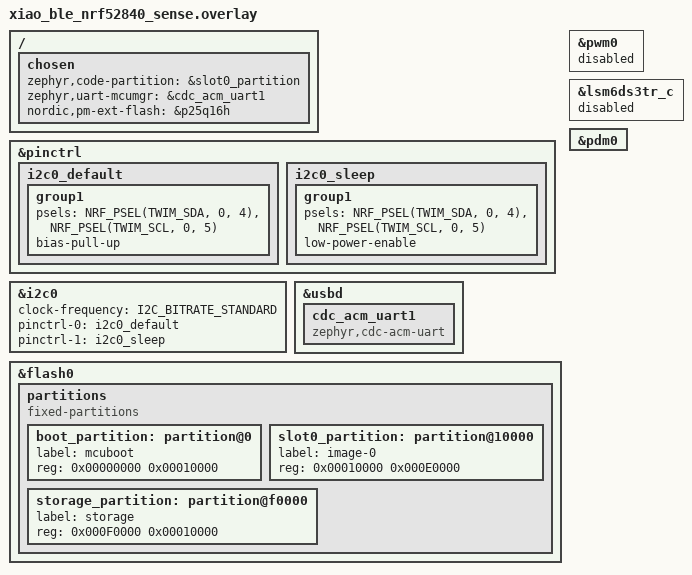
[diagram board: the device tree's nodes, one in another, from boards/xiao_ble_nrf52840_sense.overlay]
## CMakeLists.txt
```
#
# Matter AC Controller for Seeed XIAO BLE (nRF52840)
#

cmake_minimum_required(VERSION 3.20.0)

find_package(Zephyr HINTS $ENV{ZEPHYR_BASE})

project(matter-ac-controller)

# Enable GNU STD support and initialize the Matter Data Model.
include(${ZEPHYR_CONNECTEDHOMEIP_MODULE_DIR}/config/nrfconnect/app/enable-gnu-std.cmake)
include(${ZEPHYR_CONNECTEDHOMEIP_MODULE_DIR}/src/app/chip_data_model.cmake)

# Include paths
set(MATTER_COMMONS_SRC_DIR ${ZEPHYR_NRF_MODULE_DIR}/samples/matter/common/src)
target_include_directories(app PRIVATE
    src
    ${MATTER_COMMONS_SRC_DIR}
)

# Common Matter sources (cherry-picked to avoid DK library dependency)
target_sources(app PRIVATE
    ${MATTER_COMMONS_SRC_DIR}/app/task_executor.cpp
    ${MATTER_COMMONS_SRC_DIR}/app/matter_init.cpp
    ${MATTER_COMMONS_SRC_DIR}/app/matter_event_handler.cpp
)

# Application sources
target_sources(app PRIVATE
    src/main.cpp
    src/app_task.cpp
    src/hw_pairing.cpp
    src/zcl_callbacks.cpp
    src/ir_driver.cpp
    src/ir_protocol.cpp
    src/scd40_manager.cpp
    src/pdm_manager.cpp
    src/shell_commands.cpp
    src/identify_led.cpp
    src/qrcodegen.c
)

set_source_files_properties(
    src/main.cpp
    src/app_task.cpp
    src/hw_pairing.cpp
    src/zcl_callbacks.cpp
    src/ir_driver.cpp
    src/ir_protocol.cpp
    src/scd40_manager.cpp
    src/pdm_manager.cpp
    src/shell_commands.cpp
    src/identify_led.cpp
    PROPERTIES COMPILE_OPTIONS "-Wall;-Wextra;-Werror;-Wno-unused-parameter;-Wno-missing-field-initializers"
)

chip_configure_data_model(app
    INCLUDE_SERVER
    BYPASS_IDL
    GEN_DIR src/zap-generated
    ZAP_FILE ${CMAKE_CURRENT_SOURCE_DIR}/src/ac_controller.zap
)
```

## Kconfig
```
#
# Matter AC Controller
#
mainmenu "Matter AC Controller"

# Sample configuration used for Thread networking
if NET_L2_OPENTHREAD

choice OPENTHREAD_NORDIC_LIBRARY_CONFIGURATION
    default OPENTHREAD_NORDIC_LIBRARY_MTD
endchoice

choice OPENTHREAD_DEVICE_TYPE
    default OPENTHREAD_MTD
endchoice

endif # NET_L2_OPENTHREAD

source "${ZEPHYR_CONNECTEDHOMEIP_MODULE_DIR}/config/nrfconnect/chip-module/Kconfig.features"
source "${ZEPHYR_CONNECTEDHOMEIP_MODULE_DIR}/config/nrfconnect/chip-module/Kconfig.defaults"
source "${ZEPHYR_NRF_MODULE_DIR}/samples/matter/common/src/Kconfig"
source "Kconfig.zephyr"
```

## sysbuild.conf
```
SB_CONFIG_MATTER=y
SB_CONFIG_MATTER_OTA=n

SB_CONFIG_BOOTLOADER_MCUBOOT=y
SB_CONFIG_MCUBOOT_MODE_OVERWRITE_ONLY=y
SB_CONFIG_BOOT_SIGNATURE_TYPE_NONE=y
```

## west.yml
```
manifest:
  version: "0.13"

  remotes:
    - name: nrfconnect
      url-base: https://github.com/nrfconnect

  projects:
    - name: nrf
      remote: nrfconnect
      repo-path: sdk-nrf
      revision: v3.3.0
      import: true

  self:
    path: matter-ac-ncs
```

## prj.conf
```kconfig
#
# Matter AC Controller — prj.conf
#

# --- Matter core ---
CONFIG_CHIP=y
CONFIG_PSA_WANT_ALG_PBKDF2_HMAC=y
CONFIG_PSA_WANT_ALG_HMAC=y
CONFIG_OPENTHREAD_MTD=y
CONFIG_CHIP_ENABLE_PAIRING_AUTOSTART=y
CONFIG_CHIP_PROJECT_CONFIG="src/chip_project_config.h"
CONFIG_STD_CPP17=y

# Extended BLE advertising (improves commissioning reliability)
CONFIG_CHIP_BLE_EXT_ADVERTISING=y
CONFIG_CHIP_BLE_ADVERTISING_DURATION=60

# Device identity
# Vendor/Product IDs are Kconfig int → decimal
CONFIG_CHIP_DEVICE_VENDOR_ID=65521
CONFIG_CHIP_DEVICE_PRODUCT_ID=32769
CONFIG_CHIP_DEVICE_VENDOR_NAME="BRAZENRAKE"
CONFIG_CHIP_DEVICE_PRODUCT_NAME="IR AC Controller"
CONFIG_CHIP_DEVICE_SERIAL_NUMBER="MATTER-AC-001"
CONFIG_CHIP_DEVICE_SOFTWARE_VERSION=1
CONFIG_CHIP_DEVICE_SOFTWARE_VERSION_STRING="1.0.0"
# Discriminator and passcode are derived at runtime from the FICR hardware ID
# by HwPairing::Init() — these Kconfig values are fallback placeholders only.
CONFIG_CHIP_DEVICE_DISCRIMINATOR=0xF00
CONFIG_CHIP_DEVICE_SPAKE2_PASSCODE=20202021

# --- OpenThread features required for Matter commissioning ---
# SLAAC: auto-configure OMR address from the HomePod's on-mesh prefix so SRP
# registers the OMR address (not just ML-EID). Without this the iPhone (Wi-Fi)
# cannot reach the device via the HomePod's backbone router and CASE never starts.
CONFIG_OPENTHREAD_SLAAC=y

# --- Features we do NOT need ---
CONFIG_CHIP_OTA_REQUESTOR=n
CONFIG_CHIP_NFC_ONBOARDING_PAYLOAD=n
CONFIG_CHIP_FACTORY_DATA_NONE=y
CONFIG_BOOTLOADER_MCUBOOT=y
CONFIG_DK_LIBRARY=n

# --- Bluetooth ---
CONFIG_BT_DEVICE_NAME="MatterAC"

# --- Logging via USB-CDC ---
CONFIG_CBPRINTF_FP_SUPPORT=y
CONFIG_LOG=y
CONFIG_LOG_MODE_DEFERRED=y
CONFIG_LOG_RUNTIME_FILTERING=y

# --- USB-CDC shell (uses board's USB_DEVICE_STACK_NEXT default in NCS v3.3.0) ---
CONFIG_UART_LINE_CTRL=y
CONFIG_SHELL=y
CONFIG_SHELL_BACKEND_SERIAL=y
CONFIG_MATTER_LOG_LEVEL_ERR=y
CONFIG_SHELL_MINIMAL=n
CONFIG_LOG_CMDS=y
CONFIG_KERNEL_SHELL=y
CONFIG_SHELL_BACKEND_SERIAL_CHECK_DTR=y
# Second CDC ACM instance for MCUmgr DFU on ACM1 (zephyr,uart-mcumgr in overlay)
CONFIG_CDC_ACM_SERIAL_MULTIPLE_INSTANCES=y

# --- I2C for SCD40 sensor ---
CONFIG_I2C=y

# --- PDM microphone + FFT-based CFAR ACK detector ---
CONFIG_NRFX_PDM=y
CONFIG_GPIO=y
CONFIG_CMSIS_DSP=y
CONFIG_CMSIS_DSP_TRANSFORM=y

# --- Commissioning debug logging ---
# When debugging: uncomment all and set LOG_DEFAULT_LEVEL=3.
# Gives OpenThread join state machine + Matter CommissioningComplete /
# FailSafe / CASE session events. Raise LOG_BUFFER_SIZE for the verbosity.
CONFIG_LOG_DEFAULT_LEVEL=1
# CONFIG_LOG_DEFAULT_LEVEL=3
# CONFIG_OPENTHREAD_DEBUG=y
# CONFIG_OPENTHREAD_LOG_LEVEL_INFO=y
# CONFIG_LOG_BUFFER_SIZE=16384
# CONFIG_MATTER_LOG_LEVEL_INF=y

# --- Stack / safety ---
CONFIG_THREAD_NAME=y
CONFIG_MPU_STACK_GUARD=y
CONFIG_RESET_ON_FATAL_ERROR=n

# --- SMP/MCUmgr for DFU over USB-CDC ACM1 ---
CONFIG_MCUMGR=y
CONFIG_MCUMGR_GRP_IMG=y
CONFIG_MCUMGR_GRP_OS=y
CONFIG_IMG_MANAGER=y
CONFIG_NET_BUF=y
CONFIG_ZCBOR=y
CONFIG_CRC=y
CONFIG_FLASH_MAP=y
CONFIG_STREAM_FLASH=y
CONFIG_FLASH=y
CONFIG_SETTINGS=y
CONFIG_BASE64=y
CONFIG_MCUMGR_TRANSPORT_UART=y
CONFIG_MCUMGR_TRANSPORT_UART_MTU=2048
CONFIG_MCUMGR_TRANSPORT_NETBUF_SIZE=2048
CONFIG_UART_MCUMGR_RX_BUF_SIZE=512
CONFIG_UART_MCUMGR_RX_BUF_COUNT=8
```

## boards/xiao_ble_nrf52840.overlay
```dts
/*
 * Devicetree overlay for Seeed XIAO BLE — Matter AC Controller
 *
 * - Disable USB (save RAM, we use J-Link + RTT)
 * - Reclaim flash from SoftDevice + bootloader
 * - Disable Zephyr PWM0 (IR driver uses NRF_PWM0 registers directly)
 * - I2C0 (TWIM0) for SCD40 sensor (P0.04 SDA / P0.05 SCL)
 */

/* Remap I2C0 pins to P0.04/P0.05 (board default is P0.07/P0.27 for
 * the Sense variant's IMU) and enable internal pull-ups. */
&pinctrl {
    i2c0_default: i2c0_default {
        group1 {
            psels = <NRF_PSEL(TWIM_SDA, 0, 4)>,
                    <NRF_PSEL(TWIM_SCL, 0, 5)>;
            bias-pull-up;
        };
    };
    i2c0_sleep: i2c0_sleep {
        group1 {
            psels = <NRF_PSEL(TWIM_SDA, 0, 4)>,
                    <NRF_PSEL(TWIM_SCL, 0, 5)>;
            low-power-enable;
        };
    };
};

&i2c0 {
    status = "okay";
    clock-frequency = <I2C_BITRATE_STANDARD>;
    pinctrl-0 = <&i2c0_default>;
    pinctrl-1 = <&i2c0_sleep>;
    pinctrl-names = "default", "sleep";
};

/* USB-CDC: shell on ACM0 (usb_cdc_acm_uart, via board DTS), SMP/DFU on ACM1 */
&usbd {
    status = "okay";
    cdc_acm_uart1: cdc_acm_uart1 {
        compatible = "zephyr,cdc-acm-uart";
    };
};

/* Replace Adafruit-layout partitions with MCUboot-compatible labels.
 * Addresses must match pm_static_xiao_ble_nrf52840_sense.yml.
 * image_signing.cmake needs slot0_partition to determine the slot size. */
&flash0 {
    /delete-node/ partitions;

    partitions {
        compatible = "fixed-partitions";
        #address-cells = <1>;
        #size-cells = <1>;

        boot_partition: partition@0 {
            label = "mcuboot";
            reg = <0x00000000 0x00010000>;
        };

        slot0_partition: partition@10000 {
            label = "image-0";
            reg = <0x00010000 0x000E0000>;
        };

        storage_partition: partition@f0000 {
            label = "storage";
            reg = <0x000F0000 0x00010000>;
        };
    };
};

/ {
    chosen {
        zephyr,code-partition = &slot0_partition;
        zephyr,uart-mcumgr = &cdc_acm_uart1;
        nordic,pm-ext-flash = &p25q16h;
    };
};

/* Disable Zephyr PWM0 — the IR driver configures NRF_PWM0 registers
 * directly to work around the polarity trick needed for 0% duty. */
&pwm0 { status = "disabled"; };
```

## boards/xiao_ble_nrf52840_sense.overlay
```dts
/*
 * Devicetree overlay for Seeed XIAO BLE Sense — Matter AC Controller
 *
 * Extends the base XIAO BLE settings with PDM microphone enablement.
 * All other settings (I2C remap, USB-CDC dual-port, PWM0 disable)
 * are identical to xiao_ble_nrf52840.overlay.
 *
 * PDM pinctrl (pdm0_default / pdm0_sleep) is already defined in:
 *   zephyr/boards/seeed/xiao_ble/xiao_ble-pinctrl.dtsi (lines 55–68)
 * We only need to set status = "okay" here.
 */

/* Remap I2C0 pins to P0.04/P0.05 (board default is P0.07/P0.27 for
 * the Sense variant's IMU) and enable internal pull-ups. */
&pinctrl {
    i2c0_default: i2c0_default {
        group1 {
            psels = <NRF_PSEL(TWIM_SDA, 0, 4)>,
                    <NRF_PSEL(TWIM_SCL, 0, 5)>;
            bias-pull-up;
        };
    };
    i2c0_sleep: i2c0_sleep {
        group1 {
            psels = <NRF_PSEL(TWIM_SDA, 0, 4)>,
                    <NRF_PSEL(TWIM_SCL, 0, 5)>;
            low-power-enable;
        };
    };
};

&i2c0 {
    status = "okay";
    clock-frequency = <I2C_BITRATE_STANDARD>;
    pinctrl-0 = <&i2c0_default>;
    pinctrl-1 = <&i2c0_sleep>;
    pinctrl-names = "default", "sleep";

};

/* USB-CDC: shell on ACM0 (usb_cdc_acm_uart, via board DTS), SMP/DFU on ACM1 */
&usbd {
    status = "okay";
    cdc_acm_uart1: cdc_acm_uart1 {
        compatible = "zephyr,cdc-acm-uart";
    };
};

/* Replace Adafruit-layout partitions with MCUboot-compatible labels.
 * Addresses must match pm_static_xiao_ble_nrf52840_sense.yml.
 * image_signing.cmake needs slot0_partition to determine the slot size. */
&flash0 {
    /delete-node/ partitions;

    partitions {
        compatible = "fixed-partitions";
        #address-cells = <1>;
        #size-cells = <1>;

        boot_partition: partition@0 {
            label = "mcuboot";
            reg = <0x00000000 0x00010000>;
        };

        slot0_partition: partition@10000 {
            label = "image-0";
            reg = <0x00010000 0x000E0000>;
        };

        storage_partition: partition@f0000 {
            label = "storage";
            reg = <0x000F0000 0x00010000>;
        };
    };
};

/ {
    chosen {
        zephyr,code-partition = &slot0_partition;
        zephyr,uart-mcumgr = &cdc_acm_uart1;
        nordic,pm-ext-flash = &p25q16h;
    };
};


/* Disable Zephyr PWM0 — the IR driver configures NRF_PWM0 registers
 * directly to work around the polarity trick needed for 0% duty. */
&pwm0 { status = "disabled"; };

/* IMU is on I2C0 which is remapped to SCD40 pins — disable to suppress init error. */
&lsm6ds3tr_c { status = "disabled"; };

/* Enable PDM0 — pinctrl already defined in xiao_ble-pinctrl.dtsi.
 * The Sense board DTS sets clock-source and pinctrl; we only add status. */
&pdm0 {
    status = "okay";
};
```

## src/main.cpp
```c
/*
 * Matter AC Controller — main entry point.
 */

#include "app_task.h"

#include <zephyr/logging/log.h>

LOG_MODULE_REGISTER(app, CONFIG_MATTER_LOG_LEVEL);

int main() {

    CHIP_ERROR err = AppTask::Instance().StartApp();

    LOG_ERR("Exited with code %" CHIP_ERROR_FORMAT, err.Format());
    return err == CHIP_NO_ERROR ? EXIT_SUCCESS : EXIT_FAILURE;
}
```

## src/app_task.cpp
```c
/*
 * Matter AC Controller — application task.
 *
 * Simplified from the Nordic thermostat sample: no DK buttons/LEDs,
 * no temperature sensor manager, no binding handler.  Initializes
 * the Matter stack, IR driver, SCD40 sensor, and runs the task loop.
 */

#include "app_task.h"
#include "hw_pairing.h"
#include "ir_driver.h"
#include "scd40_manager.h"
#include "pdm_manager.h"

#include "app/matter_init.h"
#include "app/task_executor.h"
#include "identify_led.h"

#include <app/DefaultTimerDelegate.h>
#include <app/clusters/identify-server/IdentifyCluster.h>
#include <data-model-providers/codegen/CodegenDataModelProvider.h>
#include <setup_payload/OnboardingCodesUtil.h>

#include <zephyr/logging/log.h>

extern void zcl_callbacks_ready(void);

/* nrf_matter_cluster_init_run_all is called by matter_init.cpp::StartServer() in NCS v3.3.0.
 * We don't register any entries via NRF_MATTER_CLUSTER_INIT so this is a no-op. */
extern "C" bool nrf_matter_cluster_init_run_all(void) { return true; }

LOG_MODULE_DECLARE(app, CONFIG_MATTER_LOG_LEVEL);

using namespace ::chip;
using namespace ::chip::app;
using namespace ::chip::DeviceLayer;

namespace {
constexpr EndpointId kThermostatEndpointId = 1;

/* Identify cluster — new ServerClusterInterface model (NCS v3.3.0 / CHIP SDK 2.9.x).
 * ZAP marks Identify attributes EXTERNAL_STORAGE, so they must be served by a registered
 * ServerClusterInterface; the legacy Identify shim silently swallows Register() errors.
 * Using RegisteredServerCluster directly mirrors the NCS thermostat sample pattern and
 * surfaces any registration failure. Endpoints 1-3 all carry Identify in the ZAP config. */

chip::app::DefaultTimerDelegate gIdTimer1, gIdTimer2, gIdTimer3;
chip::app::RegisteredServerCluster<chip::app::Clusters::IdentifyCluster>
    gIdCluster1(chip::app::Clusters::IdentifyCluster::Config(1, gIdTimer1)
        .WithDelegate(&identify_led_delegate())
        .WithIdentifyType(chip::app::Clusters::Identify::IdentifyTypeEnum::kVisibleIndicator)),
    gIdCluster2(chip::app::Clusters::IdentifyCluster::Config(2, gIdTimer2)
        .WithDelegate(&identify_led_delegate())
        .WithIdentifyType(chip::app::Clusters::Identify::IdentifyTypeEnum::kVisibleIndicator)),
    gIdCluster3(chip::app::Clusters::IdentifyCluster::Config(3, gIdTimer3)
        .WithDelegate(&identify_led_delegate())
        .WithIdentifyType(chip::app::Clusters::Identify::IdentifyTypeEnum::kVisibleIndicator));

} /* namespace */

CHIP_ERROR AppTask::Init() {
    /* Derive discriminator + SPAKE2+ passcode from FICR hardware ID. */
    ReturnErrorOnFailure(HwPairing::Init());

    /* Initialize and start the Matter server. */
    ReturnErrorOnFailure(Nrf::Matter::PrepareServer());
    ReturnErrorOnFailure(Nrf::Matter::StartServer());

    /* Register Identify clusters for all endpoints that declare them in the ZAP config.
     * Must happen after StartServer() so the registry context is set and Startup() fires. */
    {
        auto & reg = CodegenDataModelProvider::Instance().Registry();
        for (auto * entry : { &gIdCluster1.Registration(),
                               &gIdCluster2.Registration(),
                               &gIdCluster3.Registration() }) {
            CHIP_ERROR err = reg.Register(*entry);
            if (err != CHIP_NO_ERROR) {
                LOG_ERR("Identify Register failed: %" CHIP_ERROR_FORMAT, err.Format());
            }
        }
    }

    /* Initialize IR driver (PWM-based 38kHz carrier on P0.02). */
    int ret = ir_driver_init();
    if (ret) {
        LOG_ERR("IR driver init failed: %d", ret);
    }

    /* Initialize SCD40 sensor (I2C0, 30s polling). */
    ret = scd40_manager_init();
    if (ret) {
        LOG_ERR("SCD40 init failed: %d (sensor may not be connected)", ret);
    }

    /* Initialize PDM microphone (2kHz beep detection for IR ACK). */
    pdm_manager_init();

    /* Enable IR transmission now that init is complete.
     * This prevents MatterPostAttributeChangeCallback from firing
     * IR during Matter stack attribute restoration at boot. */
    zcl_callbacks_ready();

    return CHIP_NO_ERROR;
}

CHIP_ERROR AppTask::StartApp() {
    ReturnErrorOnFailure(Init());

    while (true) {
        Nrf::DispatchNextTask();
    }

    return CHIP_NO_ERROR;
}
```

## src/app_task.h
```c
/*
 * Matter AC Controller — application task.
 */

#pragma once

#include <platform/CHIPDeviceLayer.h>

class AppTask {
public:
	static AppTask &Instance()
	{
		static AppTask sAppTask;
		return sAppTask;
	}

	CHIP_ERROR StartApp();

private:
	CHIP_ERROR Init();
};
```

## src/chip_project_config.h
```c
/*
 * CHIP project configuration overrides for Matter AC Controller.
 */

#pragma once

#define CHIP_DEVICE_CONFIG_DYNAMIC_ENDPOINT_COUNT 0

/* MRP intervals for Thread MTD.
 *
 * NCS v3.3.0 Matter SDK (v2.9.2): GetLocalMRPConfig() returns Missing() when
 * the local config matches GetDefaultMRPConfig() (idle=500ms, active=300ms).
 * Missing() causes CopyTxtRecord to skip SII/SAI/SAT from the operational SRP
 * advertisement, and Apple Home will not initiate CASE without those TXT records.
 *
 * Setting idle to 4300ms (typical Thread MTD polling interval recommendation)
 * makes the config differ from default, so GetLocalMRPConfig() returns Value()
 * and the TXT records are included in the SRP advertisement.
 */
#define CHIP_CONFIG_MRP_LOCAL_IDLE_RETRY_INTERVAL   (4300_ms32)
#define CHIP_CONFIG_MRP_LOCAL_ACTIVE_RETRY_INTERVAL (300_ms32)
```

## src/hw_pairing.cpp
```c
/*
 * Derive Matter pairing credentials from the nRF52840 FICR hardware device ID.
 *
 * The FICR DEVICEID registers hold a 64-bit value that is unique per die and
 * programmed at the factory.  We domain-separate FNV-1a hashes of those bytes
 * to produce a 12-bit discriminator, a valid passcode, a 16-byte PBKDF2 salt,
 * and a SPAKE2+ verifier — all without any runtime storage or factory data.
 */

#include "hw_pairing.h"

#include <crypto/CHIPCryptoPAL.h>
#include <lib/core/CHIPError.h>
#include <lib/support/Span.h>
#include <platform/CommissionableDataProvider.h>

#include <nrfx.h>
#include <zephyr/logging/log.h>

#include <string.h>

LOG_MODULE_REGISTER(hw_pairing, CONFIG_LOG_DEFAULT_LEVEL);

using namespace chip;
using namespace chip::Crypto;
using namespace chip::DeviceLayer;

/* ---- FNV-1a 32-bit ---------------------------------------------------- */

static constexpr uint32_t kFnvBasis = 2166136261u;
static constexpr uint32_t kFnvPrime = 16777619u;

static uint32_t fnv1a32(const uint8_t *data, size_t len, uint32_t seed)
{
    uint32_t h = seed;
    for (size_t i = 0; i < len; i++) {
        h ^= data[i];
        h *= kFnvPrime;
    }
    return h;
}

/* ---- Passcode sanitisation -------------------------------------------- */

/* Matter spec Table 39 — forbidden passcodes. */
static constexpr uint32_t kForbidden[] = {
    00000000u, 11111111u, 22222222u, 33333333u, 44444444u,
    55555555u, 66666666u, 77777777u, 88888888u, 99999999u,
    12345678u, 87654321u,
};

static uint32_t make_passcode(uint32_t h)
{
    /* Map to [1, 99999998]. */
    uint32_t code = (h % 99999998u) + 1u;

    for (uint32_t f : kForbidden) {
        if (code == f) {
            /* Bump by one; no two forbidden values are adjacent. */
            code = (code % 99999998u) + 1u;
            break;
        }
    }
    return code;
}

/* ---- CommissionableDataProvider --------------------------------------- */

namespace {

class HwCommissionableDataProvider : public CommissionableDataProvider
{
public:
    CHIP_ERROR Init();

    CHIP_ERROR GetSetupDiscriminator(uint16_t & discriminator) override;
    CHIP_ERROR SetSetupDiscriminator(uint16_t) override { return CHIP_ERROR_NOT_IMPLEMENTED; }
    CHIP_ERROR GetSpake2pIterationCount(uint32_t & iterationCount) override;
    CHIP_ERROR GetSpake2pSalt(MutableByteSpan & saltBuf) override;
    CHIP_ERROR GetSpake2pVerifier(MutableByteSpan & verifierBuf,
                                  size_t & verifierLen) override;
    CHIP_ERROR GetSetupPasscode(uint32_t & passcode) override;
    CHIP_ERROR SetSetupPasscode(uint32_t) override { return CHIP_ERROR_NOT_IMPLEMENTED; }

private:
    static constexpr uint32_t kIterations   = 1000;
    static constexpr size_t   kSaltLen      = 16;
    static constexpr size_t   kVerifierLen  = kSpake2p_VerifierSerialized_Length;

    uint16_t mDiscriminator = 0;
    uint32_t mPasscode      = 0;
    uint8_t  mSalt[kSaltLen];
    uint8_t  mVerifier[kVerifierLen];
    bool     mRawReady     = false;
    bool     mVerifierReady = false;
};

HwCommissionableDataProvider gProvider;

} // namespace

CHIP_ERROR HwCommissionableDataProvider::Init()
{
    /* Read the 64-bit FICR unique device ID. */
    uint32_t id0 = NRF_FICR->DEVICEID[0];
    uint32_t id1 = NRF_FICR->DEVICEID[1];

    uint8_t raw[8];
    memcpy(raw,     &id0, 4);
    memcpy(raw + 4, &id1, 4);

    /* Discriminator — 12 bits. */
    uint32_t hDisc  = fnv1a32(raw, sizeof(raw), 0xD15C0001u);
    mDiscriminator  = static_cast<uint16_t>(hDisc & 0x0FFFu);

    /* Passcode — [1, 99999998] minus forbidden values. */
    uint32_t hPass = fnv1a32(raw, sizeof(raw), 0xD15C0002u);
    mPasscode      = make_passcode(hPass);

    /* Salt — 16 bytes from four domain-separated hashes. */
    for (int i = 0; i < 4; i++) {
        uint32_t hs = fnv1a32(raw, sizeof(raw),
                               static_cast<uint32_t>(0xD15C0003u + i));
        memcpy(mSalt + (i * 4), &hs, 4);
    }

    mRawReady = true;

    LOG_INF("HW pairing: discriminator=%04u  passcode=%08u",
            mDiscriminator, mPasscode);
    return CHIP_NO_ERROR;
}

CHIP_ERROR HwCommissionableDataProvider::GetSetupDiscriminator(uint16_t & discriminator)
{
    VerifyOrReturnError(mRawReady, CHIP_ERROR_INCORRECT_STATE);
    discriminator = mDiscriminator;
    return CHIP_NO_ERROR;
}

CHIP_ERROR HwCommissionableDataProvider::GetSpake2pIterationCount(uint32_t & iterationCount)
{
    iterationCount = kIterations;
    return CHIP_NO_ERROR;
}

CHIP_ERROR HwCommissionableDataProvider::GetSpake2pSalt(MutableByteSpan & saltBuf)
{
    VerifyOrReturnError(mRawReady, CHIP_ERROR_INCORRECT_STATE);
    VerifyOrReturnError(saltBuf.size() >= kSaltLen, CHIP_ERROR_BUFFER_TOO_SMALL);
    memcpy(saltBuf.data(), mSalt, kSaltLen);
    saltBuf.reduce_size(kSaltLen);
    return CHIP_NO_ERROR;
}

CHIP_ERROR HwCommissionableDataProvider::GetSpake2pVerifier(MutableByteSpan & verifierBuf,
                                                             size_t & verifierLen)
{
    VerifyOrReturnError(mRawReady, CHIP_ERROR_INCORRECT_STATE);

    if (!mVerifierReady) {
        /* PSA is now initialized (called after PrepareServer). */
        LOG_INF("HW pairing: computing SPAKE2+ verifier (PBKDF2, %u iterations)...", kIterations);
        Spake2pVerifier verifier;
        CHIP_ERROR err = verifier.Generate(kIterations, ByteSpan(mSalt, kSaltLen), mPasscode);
        if (err != CHIP_NO_ERROR) {
            LOG_ERR("HW pairing: Spake2pVerifier::Generate failed: %" CHIP_ERROR_FORMAT, err.Format());
            return err;
        }
        MutableByteSpan span(mVerifier, kVerifierLen);
        ReturnErrorOnFailure(verifier.Serialize(span));
        mVerifierReady = true;
        LOG_INF("HW pairing: verifier ready");
    }

    VerifyOrReturnError(verifierBuf.size() >= kVerifierLen, CHIP_ERROR_BUFFER_TOO_SMALL);
    memcpy(verifierBuf.data(), mVerifier, kVerifierLen);
    verifierBuf.reduce_size(kVerifierLen);
    verifierLen = kVerifierLen;
    return CHIP_NO_ERROR;
}

CHIP_ERROR HwCommissionableDataProvider::GetSetupPasscode(uint32_t & passcode)
{
    VerifyOrReturnError(mRawReady, CHIP_ERROR_INCORRECT_STATE);
    passcode = mPasscode;
    return CHIP_NO_ERROR;
}

/* ---- Public API ------------------------------------------------------- */

CHIP_ERROR HwPairing::Init()
{
    ReturnErrorOnFailure(gProvider.Init());
    SetCommissionableDataProvider(&gProvider);
    return CHIP_NO_ERROR;
}
```

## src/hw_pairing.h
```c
/*
 * Derive discriminator and SPAKE2+ passcode from the nRF52840 FICR hardware
 * device ID so every unit gets unique pairing credentials without factory data.
 */

#pragma once

#include <lib/core/CHIPError.h>

namespace HwPairing {

/* Compute credentials from FICR, build the SPAKE2+ verifier, and register a
 * CommissionableDataProvider.  Must be called before PrepareServer(). */
CHIP_ERROR Init();

} // namespace HwPairing
```

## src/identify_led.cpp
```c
/*
 * Identify cluster feedback: 2 Hz blue LED blink.
 *
 * Implements IdentifyDelegate for the new ServerClusterInterface model used
 * in NCS v3.3.0 / CHIP SDK 2.9.x.  The LED blinks while the Matter Identify
 * timer counts down (OnIdentifyStart / OnIdentifyStop) and also when triggered
 * directly by the "matter identify" shell command (identify_led_trigger).
 */

#include <zephyr/drivers/gpio.h>
#include <zephyr/kernel.h>

#include <app/clusters/identify-server/IdentifyCluster.h>
#include "identify_led.h"

using namespace chip::app::Clusters;

/* Blue LED: P0.30, active-low (common anode RGB on XIAO nRF52840). */
static const struct gpio_dt_spec led_blue = GPIO_DT_SPEC_GET(DT_ALIAS(led2), gpios);

static struct k_timer blink_timer;
static struct k_timer stop_timer;   /* auto-stop for shell-triggered blink */
static struct k_work  blink_work;
static bool           blink_on;

static void blink_work_fn(struct k_work *)
{
    blink_on = !blink_on;
    gpio_pin_set_dt(&led_blue, (int)blink_on);
}

static void blink_timer_fn(struct k_timer *)
{
    k_work_submit(&blink_work);
}

static void stop_timer_fn(struct k_timer *)
{
    k_timer_stop(&blink_timer);
    gpio_pin_set_dt(&led_blue, 0);
}

static void start_blink()
{
    k_timer_stop(&stop_timer);
    blink_on = false;
    k_timer_start(&blink_timer, K_MSEC(250), K_MSEC(250));
}

static void stop_blink()
{
    k_timer_stop(&stop_timer);
    k_timer_stop(&blink_timer);
    gpio_pin_set_dt(&led_blue, 0);
}

class LedIdentifyDelegate : public IdentifyDelegate
{
public:
    void OnIdentifyStart(IdentifyCluster &) override { start_blink(); }
    void OnIdentifyStop(IdentifyCluster &) override  { stop_blink(); }
    void OnTriggerEffect(IdentifyCluster &) override { start_blink(); }
    bool IsTriggerEffectEnabled() const override     { return true; }
};

static LedIdentifyDelegate gDelegate;

IdentifyDelegate & identify_led_delegate()
{
    return gDelegate;
}

void identify_led_trigger()
{
    start_blink();
    k_timer_start(&stop_timer, K_SECONDS(5), K_NO_WAIT);
}

static int identify_led_init(void)
{
    if (!gpio_is_ready_dt(&led_blue)) {
        return -ENODEV;
    }
    gpio_pin_configure_dt(&led_blue, GPIO_OUTPUT_INACTIVE);
    k_work_init(&blink_work, blink_work_fn);
    k_timer_init(&blink_timer, blink_timer_fn, NULL);
    k_timer_init(&stop_timer, stop_timer_fn, NULL);
    return 0;
}

SYS_INIT(identify_led_init, APPLICATION, 91);
```

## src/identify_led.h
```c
#pragma once

#ifdef __cplusplus
#include <app/clusters/identify-server/IdentifyCluster.h>
chip::app::Clusters::IdentifyDelegate & identify_led_delegate();
extern "C" {
#endif

/* Start a 5-second 2Hz blue blink (auto-stops). Used by the shell command. */
void identify_led_trigger();

#ifdef __cplusplus
}
#endif
```

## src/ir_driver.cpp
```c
/*
 * IR transmit driver for nRF52840 — PWM-based 38kHz carrier.
 *
 * Carrier ON:  PWM at 38kHz, 33% duty (falling polarity, compare=140)
 * Carrier OFF: rising polarity, compare=0 → output always LOW
 *
 * The nRF52840 PWM has a quirk: with falling polarity and compare=0
 * the output is always HIGH (not LOW).  We use rising polarity with
 * compare=0 for true 0%.
 *
 * We write duty values directly via NRF_PWM0 registers to bypass the
 * Zephyr PWM API's inability to express this polarity trick.
 */

#include "ir_driver.h"
#include "ir_protocol.h"
#include "pdm_manager.h"

#include <zephyr/kernel.h>
#include <zephyr/logging/log.h>
#include <nrfx_pwm.h>
#include <hal/nrf_pwm.h>

#include <app-common/zap-generated/attributes/Accessors.h>
#include <platform/CHIPDeviceLayer.h>

LOG_MODULE_REGISTER(ir_driver, CONFIG_LOG_DEFAULT_LEVEL);

using namespace chip::app::Clusters;
using namespace chip::DeviceLayer;

#define IR_RETRY_COUNT    10
#define IR_ACK_TIMEOUT_MS 1000

/* 38kHz carrier constants (PWM clock = 16MHz, prescaler DIV_1) */
static const uint16_t ir_countertop = 421U; /* 16 000 000 / 38 000 ≈ 421 → 38 004 Hz */

/*
 * nRF52840 PWM duty register — bit 15 selects compare polarity:
 *   0 = falling (output HIGH at period start, LOW at compare)
 *   1 = rising  (output LOW at period start, HIGH at compare)
 */
#define CARRIER_ON  140U      /* falling polarity, 140/421 ≈ 33% */
#define CARRIER_OFF (0x8000U) /* rising polarity, compare=0 → always LOW */

static nrf_pwm_values_common_t duty_value;
static nrf_pwm_sequence_t      seq;

/* --- Dispatch thread: non-blocking enqueue from Matter thread --- */
static K_SEM_DEFINE(ir_dispatch_sem, 0, 1);
static K_MUTEX_DEFINE(ir_dispatch_mutex);
static struct IrPulse ir_pending_buf[IR_MAX_PULSES];
static struct IrPulse ir_active_buf[IR_MAX_PULSES];
static uint16_t       ir_pending_count;
static uint16_t       ir_active_count;

static void ir_dispatch_thread_fn(void *, void *, void *) {
    while (true) {
        k_sem_take(&ir_dispatch_sem, K_FOREVER);
        k_mutex_lock(&ir_dispatch_mutex, K_FOREVER);
        ir_active_count = ir_pending_count;
        memcpy(ir_active_buf, ir_pending_buf, ir_pending_count * sizeof(struct IrPulse));
        k_mutex_unlock(&ir_dispatch_mutex);
        ir_send_command(ir_active_buf, ir_active_count);
    }
}

K_THREAD_DEFINE(ir_dispatch_thread, 1024, ir_dispatch_thread_fn, NULL, NULL, NULL,
                K_PRIO_PREEMPT(10), 0, 0);

void ir_dispatch_command(const struct IrPulse *pulses, uint16_t count) {
    k_mutex_lock(&ir_dispatch_mutex, K_FOREVER);
    ir_pending_count = count;
    memcpy(ir_pending_buf, pulses, count * sizeof(struct IrPulse));
    k_mutex_unlock(&ir_dispatch_mutex);
    k_sem_give(&ir_dispatch_sem);
}

int ir_driver_init(void) {
    NRF_PWM0->ENABLE = 1;

    /* Prescaler DIV_1 → 16 MHz clock */
    NRF_PWM0->PRESCALER  = NRF_PWM_CLK_16MHz;
    NRF_PWM0->COUNTERTOP = ir_countertop;
    NRF_PWM0->MODE       = NRF_PWM_MODE_UP;
    NRF_PWM0->DECODER =
        (NRF_PWM_LOAD_COMMON << PWM_DECODER_LOAD_Pos) | (NRF_PWM_STEP_AUTO << PWM_DECODER_MODE_Pos);
    NRF_PWM0->LOOP = 0;

    /* Point DMA at our single duty value */
    duty_value                = CARRIER_OFF;
    seq.values.p_common       = &duty_value;
    seq.length                = 1;
    seq.repeats               = 0;
    seq.end_delay             = 0;
    NRF_PWM0->SEQ[0].PTR      = (uint32_t)&duty_value;
    NRF_PWM0->SEQ[0].CNT      = 1;
    NRF_PWM0->SEQ[0].REFRESH  = 0;
    NRF_PWM0->SEQ[0].ENDDELAY = 0;

    /* Connect channel 0 to P0.02 (IR LED). */
    NRF_PWM0->PSEL.OUT[0] = (0 << PWM_PSEL_OUT_PORT_Pos) | /* Port 0 */
                            (2 << PWM_PSEL_OUT_PIN_Pos) |  /* Pin 2 */
                            (PWM_PSEL_OUT_CONNECT_Connected << PWM_PSEL_OUT_CONNECT_Pos);
    NRF_PWM0->PSEL.OUT[1] = PWM_PSEL_OUT_CONNECT_Disconnected << PWM_PSEL_OUT_CONNECT_Pos;
    NRF_PWM0->PSEL.OUT[2] = PWM_PSEL_OUT_CONNECT_Disconnected << PWM_PSEL_OUT_CONNECT_Pos;
    NRF_PWM0->PSEL.OUT[3] = PWM_PSEL_OUT_CONNECT_Disconnected << PWM_PSEL_OUT_CONNECT_Pos;

    /* Start with carrier off */
    duty_value = CARRIER_OFF;
    __DMB();
    NRF_PWM0->EVENTS_SEQEND[0]  = 0;
    NRF_PWM0->TASKS_SEQSTART[0] = 1;
    while (!NRF_PWM0->EVENTS_SEQEND[0]) {
    }

    LOG_INF("IR driver initialised (P0.02, 38kHz)");
    return 0;
}

static void load_duty(void) {
    __DMB();
    NRF_PWM0->EVENTS_SEQEND[0]  = 0;
    NRF_PWM0->TASKS_SEQSTART[0] = 1;
    while (!NRF_PWM0->EVENTS_SEQEND[0]) {
    }
}

void ir_transmit(const struct IrPulse *pulses, uint16_t count) {
    LOG_INF("IR: transmitting %u pulses", count);

    for (uint16_t i = 0; i < count; i++) {
        /* Mark: 38kHz carrier at 33% duty */
        duty_value = CARRIER_ON;
        load_duty();
        k_busy_wait(pulses[i].mark_us);

        /* Space: carrier off */
        duty_value = CARRIER_OFF;
        load_duty();
        if (pulses[i].space_us > 0) {
            k_busy_wait(pulses[i].space_us);
        }
    }

    /* Ensure carrier is off when done */
    duty_value = CARRIER_OFF;
    load_duty();

    LOG_INF("IR: transmission complete");
}

bool ir_send_command(const struct IrPulse *pulses, uint16_t count) {
    for (int attempt = 1; attempt <= IR_RETRY_COUNT; attempt++) {
        ir_transmit(pulses, count);
        pdm_manager_start_listen();
        if (pdm_manager_collect_ack(IR_ACK_TIMEOUT_MS)) {
            LOG_INF("IR: ACK received on attempt %d/%d", attempt, IR_RETRY_COUNT);
            return true;
        }
        LOG_WRN("IR: no ACK on attempt %d/%d", attempt, IR_RETRY_COUNT);
    }
    LOG_ERR("IR: command failed after %d attempts", IR_RETRY_COUNT);
    return false;
}
```

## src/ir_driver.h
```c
/*
 * IR transmit driver for nRF52840.
 *
 * Uses the PWM peripheral to generate a 38kHz carrier.  Mark/space
 * timing is handled by k_busy_wait() for microsecond precision.
 */

#pragma once

#include <stdint.h>
#include <zephyr/device.h>

/* A single mark/space pulse pair in microseconds. */
struct IrPulse {
	uint16_t mark_us;
	uint16_t space_us;
};

/**
 * Initialise the IR driver.  Call once at boot.
 * Returns 0 on success, negative errno on failure.
 */
int ir_driver_init(void);

/**
 * Transmit a sequence of mark/space pulses.
 * Blocks the calling thread for the duration of transmission (~1.2 s
 * for a full Hitachi frame).
 */
void ir_transmit(const struct IrPulse *pulses, uint16_t count);

/**
 * Transmit a command with up to IR_RETRY_COUNT attempts, waiting for a
 * 2kHz PDM ACK from the AC unit after each attempt.
 * Returns true if ACK was received, false if all retries exhausted.
 * Blocks the calling thread for the full retry sequence — call ir_dispatch_command
 * instead to enqueue from the Matter thread without blocking.
 */
bool ir_send_command(const struct IrPulse *pulses, uint16_t count);

/**
 * Non-blocking enqueue of an IR command for the dedicated dispatch thread.
 * Copies pulses into a static buffer and signals the thread; returns immediately.
 * If a command is already queued, it is replaced by the new one.
 */
void ir_dispatch_command(const struct IrPulse *pulses, uint16_t count);
```

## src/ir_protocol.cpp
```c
/*
 * Hitachi "Shirokuma-kun" AC IR protocol encoder.
 *
 * 53-byte stateless protocol:
 *   - 3-byte preamble
 *   - 25 data bytes each followed by their bitwise complement
 *   - LSB-first bit ordering
 *   - 30ms wakeup burst, then 3.38ms header, then 424 data bits + trail
 *
 * Reference: https://github.com/Braz3n/ShirokumaKunController-rs
 */

#include "ir_protocol.h"

#include <string.h>

/* Timing constants (microseconds). */
#define WAKEUP_MARK  30000U
#define WAKEUP_SPACE 49500U
#define HEADER_MARK  3380U
#define HEADER_SPACE 1700U
#define BIT_MARK     384U  /* 26us load_duty overhead + 384 ~= 410us total */
#define ONE_SPACE    1234U /* 26us + 1234 ~= 1260us total */
#define ZERO_SPACE   399U  /* 26us +  399 ~= 425us total */
#define TRAIL_MARK   BIT_MARK

/* Build the 25-byte raw data buffer for the Hitachi protocol. */
static void encode_raw(const struct AcState *state, uint8_t raw[25]) {
    memset(raw, 0, 25);

    /* Bytes 0-3: fixed preamble */
    raw[0] = 0x40;
    raw[1] = 0xFF;
    raw[2] = 0xCC;
    raw[3] = 0x92;

    /* Byte 4: update type (always full-state send) */
    raw[4] = 0x13;

    /* Byte 5: temperature */
    raw[5] = state->temp_c << 2;

    /* Bytes 6-10: unused / timer fields */

    /* Byte 11: fan speed (upper nibble) | mode (lower nibble) */
    uint8_t mode_nibble = state->power ? (uint8_t)state->mode : (uint8_t)AC_MODE_HEATING;
    raw[11]             = ((uint8_t)state->fan << 4) | mode_nibble;

    /* Byte 12: power/mode flags */
    if (!state->power) {
        raw[12] = 0xE1;
    } else if (state->mode == AC_MODE_HEATING || state->mode == AC_MODE_COOLING) {
        raw[12] = 0xF1;
    } else {
        raw[12] = 0xF0;
    }

    /* Bytes 15-24: fixed tail */
    raw[15] = 0x80;
    raw[16] = 0x03;
    raw[17] = 0x01;
    raw[18] = 0x88;
    raw[21] = 0xFF;
    raw[22] = 0xFF;
    raw[23] = 0xFF;
    raw[24] = 0xFF;
}

/* Build the 53-byte Hitachi command from raw data:
 * 3-byte preamble, then each of 25 raw bytes followed by its complement. */
static void encode_command(const struct AcState *state, uint8_t cmd[53]) {
    uint8_t raw[25];

    encode_raw(state, raw);

    /* Preamble */
    cmd[0] = 0x01;
    cmd[1] = 0x10;
    cmd[2] = 0x00;

    /* Data bytes with complements */
    for (int i = 0; i < 25; i++) {
        cmd[2 * i + 3] = raw[i];
        cmd[2 * i + 4] = ~raw[i];
    }
}

uint16_t ac_encode_pulses(const struct AcState *state, struct IrPulse *pulses) {
    uint8_t  command[53];
    uint16_t idx = 0;

    encode_command(state, command);

    /* Wakeup burst */
    pulses[idx].mark_us  = WAKEUP_MARK;
    pulses[idx].space_us = WAKEUP_SPACE;
    idx++;

    /* Header pulse */
    pulses[idx].mark_us  = HEADER_MARK;
    pulses[idx].space_us = HEADER_SPACE;
    idx++;

    /* Data bits (LSB-first for each byte) */
    for (int b = 0; b < 53; b++) {
        for (int bit = 0; bit < 8; bit++) {
            bool is_one          = (command[b] >> bit) & 1;
            pulses[idx].mark_us  = BIT_MARK;
            pulses[idx].space_us = is_one ? ONE_SPACE : ZERO_SPACE;
            idx++;
        }
    }

    /* Trail pulse */
    pulses[idx].mark_us  = TRAIL_MARK;
    pulses[idx].space_us = 0;
    idx++;

    return idx;
}
```

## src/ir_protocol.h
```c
/*
 * Hitachi "Shirokuma-kun" AC IR protocol encoder.
 *
 * Encodes a complete AC state (power, mode, temperature, fan speed) into
 * a sequence of IR mark/space pulses.  The protocol is stateless — every
 * command sends the full desired state.
 */

#pragma once

#include "ir_driver.h"
#include <stdint.h>
#include <stdbool.h>

/* AC operating modes (Hitachi byte 11, lower nibble). */
enum AcMode : uint8_t {
	AC_MODE_OFF         = 0x0,
	AC_MODE_VENTILATION = 0x1,
	AC_MODE_COOLING     = 0x3,
	AC_MODE_DEHUMIDIFY  = 0x5,
	AC_MODE_HEATING     = 0x6,
};

/* Fan speed settings (Hitachi byte 11, upper nibble). */
enum FanSpeed : uint8_t {
	FAN_SPEED_1    = 0x1,
	FAN_SPEED_2    = 0x2,
	FAN_SPEED_3    = 0x3,
	FAN_SPEED_4    = 0x4,
	FAN_SPEED_AUTO = 0x5,
	FAN_SPEED_5    = 0x6,
};

/* Complete AC state to be transmitted via IR. */
struct AcState {
	bool     power;
	AcMode   mode;
	uint8_t  temp_c;   /* 16-30 typical */
	FanSpeed fan;
};

/*
 * Maximum number of pulses in an encoded IR frame.
 * Wakeup(1) + Header(1) + 53*8 data bits(424) + trail(1) = 427.
 */
#define IR_MAX_PULSES 430

/**
 * Encode an AC state into IR pulses ready for transmission.
 *
 * @param state  The desired AC state.
 * @param pulses Output buffer (must hold at least IR_MAX_PULSES entries).
 * @return       Number of valid pulses written to the buffer.
 */
uint16_t ac_encode_pulses(const struct AcState *state, struct IrPulse *pulses);
```

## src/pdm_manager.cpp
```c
/*
 * PDM microphone manager — on-demand 2kHz ACK detector.
 *
 * Hardware: MSM261D3526HICPM-C PDM microphone on Seeed XIAO nRF52840 Sense
 *   PDM CLK:    P1.00  (pinctrl pdm0_default in xiao_ble-pinctrl.dtsi)
 *   PDM DIN:    P0.16  (pinctrl pdm0_default in xiao_ble-pinctrl.dtsi)
 *   Mic Enable: P1.10  active HIGH — must be driven manually
 *
 * Algorithm: 1024-point real FFT (CMSIS-DSP arm_rfft_fast_f32) with Hanning window.
 *   fs ≈ 16125 Hz (1.032 MHz PDM / 64), bin spacing ≈ 15.75 Hz, target bin 127 ≈ 2000 Hz.
 *   CA-CFAR detection: CUT power vs. mean of training cells on either side of target bin.
 */

#include "pdm_manager.h"

#include <zephyr/kernel.h>
#include <zephyr/drivers/gpio.h>
#include <zephyr/logging/log.h>
#include <zephyr/irq.h>
#include <zephyr/settings/settings.h>

#include <nrfx_pdm.h>
#include <hal/nrf_gpio.h>
#include <arm_math.h>
#include <math.h>
#include <cstdlib>

#ifndef M_PI
#define M_PI 3.14159265358979323846
#endif

LOG_MODULE_REGISTER(pdm_mgr, LOG_LEVEL_INF);

/* --------------------------------------------------------------------------
 * Hardware constants
 * -------------------------------------------------------------------------- */

#define PDM_CLK_PIN NRF_GPIO_PIN_MAP(1, 0)  /* P1.00 */
#define PDM_DIN_PIN NRF_GPIO_PIN_MAP(0, 16) /* P0.16 */
#define MIC_EN_PORT 1
#define MIC_EN_PIN  10 /* P1.10 active HIGH */

/* --------------------------------------------------------------------------
 * Detection constants
 * -------------------------------------------------------------------------- */

#define PDM_BUF_SAMPLES      1024
#define PDM_TARGET_BIN       127       /* round(2000 * 1024 / 16125) — 2000 Hz */
#define PDM_CFAR_GUARD_CELLS 2         /* bins each side excluded from noise estimate */
#define PDM_CFAR_TRAIN_CELLS 10        /* bins each side used for noise estimate */
#define PDM_SCALING_FACTOR   1e-6f     /* scale applied before logging */
static float detect_threshold = 25.0f; /* CFAR multiplier: N× above noise estimate */

static int pdm_settings_set(const char *name, size_t len,
                             settings_read_cb read_cb, void *cb_arg)
{
    if (strcmp(name, "threshold") == 0 && len == sizeof(float)) {
        read_cb(cb_arg, &detect_threshold, sizeof(float));
    }
    return 0;
}
SETTINGS_STATIC_HANDLER_DEFINE(pdm, "pdm", NULL, pdm_settings_set, NULL, NULL);

/* --------------------------------------------------------------------------
 * State
 * -------------------------------------------------------------------------- */

static int16_t          pdm_buf[2][PDM_BUF_SAMPLES];
static volatile uint8_t buf_ready_idx;
static volatile bool    buf_available;

static struct k_work pdm_process_work;
static struct k_sem  ack_sem;
static volatile bool pdm_capture_active;
static volatile bool pdm_verbose     = false;
static volatile bool pdm_verbose_own = false;

static arm_rfft_fast_instance_f32 fft_inst;
static float                      fft_in[PDM_BUF_SAMPLES];
static float                      fft_out[PDM_BUF_SAMPLES];
static float                      hann_window[PDM_BUF_SAMPLES];

static nrfx_pdm_t pdm_inst = NRFX_PDM_INSTANCE(NRF_PDM0);

/* --------------------------------------------------------------------------
 * Work handler — FFT + CA-CFAR, runs in system workqueue
 * -------------------------------------------------------------------------- */

static void pdm_process_work_handler(struct k_work *work) {
    ARG_UNUSED(work);

    if (!buf_available) {
        return;
    }

    unsigned int key = irq_lock();
    uint8_t      idx = buf_ready_idx;
    buf_available    = false;
    irq_unlock(key);

    /* Apply Hanning window and convert to float */
    for (int i = 0; i < PDM_BUF_SAMPLES; i++) {
        fft_in[i] = (float)pdm_buf[idx][i] * hann_window[i];
    }

    arm_rfft_fast_f32(&fft_inst, fft_in, fft_out, 0 /* forward */);

    /* CUT: magnitude squared at target bin.
     * arm_rfft_fast_f32 packs output as [Re0, ReN/2, Re1, Im1, Re2, Im2, ...] */
    float re  = fft_out[2 * PDM_TARGET_BIN];
    float im  = fft_out[2 * PDM_TARGET_BIN + 1];
    float cut = re * re + im * im;

    /* CA-CFAR: average training cells on both sides, skipping guard cells */
    float noise_sum = 0.0f;
    for (int k = PDM_TARGET_BIN - PDM_CFAR_GUARD_CELLS - PDM_CFAR_TRAIN_CELLS;
         k <= PDM_TARGET_BIN + PDM_CFAR_GUARD_CELLS + PDM_CFAR_TRAIN_CELLS; k++) {
        if (abs(k - PDM_TARGET_BIN) > PDM_CFAR_GUARD_CELLS) {
            float r = fft_out[2 * k], im_k = fft_out[2 * k + 1];
            noise_sum += r * r + im_k * im_k;
        }
    }
    float noise_est   = noise_sum / (2 * PDM_CFAR_TRAIN_CELLS);
    float cfar_thresh = noise_est * detect_threshold;

    LOG_DBG("PDM cut (x1e-6): %.2f  noise_est (x1e-6): %.2f", (double)(cut * PDM_SCALING_FACTOR),
            (double)(noise_est * PDM_SCALING_FACTOR));

    if (pdm_verbose) {
        LOG_INF("PDM cut (x1e-6): %.2f  thresh (x1e-6): %.2f%s", (double)(cut * PDM_SCALING_FACTOR),
                (double)(cfar_thresh * PDM_SCALING_FACTOR),
                cut > cfar_thresh ? "  [ABOVE THRESHOLD]" : "");
    }

    if (pdm_capture_active && cut > cfar_thresh) {
        LOG_INF("PDM: ACK detected (cut=%.2f thresh=%.2f)", (double)(cut * PDM_SCALING_FACTOR),
                (double)(cfar_thresh * PDM_SCALING_FACTOR));
        k_sem_give(&ack_sem);
    }
}

/* --------------------------------------------------------------------------
 * nrfx_pdm ISR callback — ISR context, keep minimal
 * -------------------------------------------------------------------------- */

static void pdm_event_handler(const nrfx_pdm_evt_t *evt) {
    static uint8_t next = 0;

    if (evt->buffer_requested) {
        nrfx_pdm_buffer_set(&pdm_inst, pdm_buf[next], PDM_BUF_SAMPLES);
        next ^= 1;
    }

    if (evt->buffer_released != NULL) {
        buf_ready_idx = (evt->buffer_released == pdm_buf[0]) ? 0 : 1;
        buf_available = true;
        k_work_submit(&pdm_process_work);
    }
}

/* --------------------------------------------------------------------------
 * Public API
 * -------------------------------------------------------------------------- */

void pdm_manager_start_listen(void) {
    k_sem_reset(&ack_sem);
    buf_available      = false;
    pdm_capture_active = true;

    int err = nrfx_pdm_start(&pdm_inst);
    if (err < 0) {
        LOG_ERR("PDM: nrfx_pdm_start failed: %d", err);
        pdm_capture_active = false;
    }
}

bool pdm_manager_collect_ack(uint32_t timeout_ms) {
    int rc = k_sem_take(&ack_sem, K_MSEC(timeout_ms));

    pdm_capture_active = false;

    int err = nrfx_pdm_stop(&pdm_inst);
    if (err < 0) {
        LOG_WRN("PDM: nrfx_pdm_stop unexpected error: %d", err);
    }

    return (rc == 0);
}

void pdm_manager_init(void) {
    /* --- 1. Enable microphone via P1.10 HIGH --- */
    const struct device *gpio1 = DEVICE_DT_GET(DT_NODELABEL(gpio1));

    if (!device_is_ready(gpio1)) {
        LOG_ERR("PDM: GPIO1 device not ready");
        return;
    }

    int ret = gpio_pin_configure(gpio1, MIC_EN_PIN, GPIO_OUTPUT_ACTIVE);
    if (ret) {
        LOG_ERR("PDM: Mic enable GPIO config failed: %d", ret);
        return;
    }

    gpio_pin_set(gpio1, MIC_EN_PIN, 1);
    LOG_INF("PDM: Mic enable (P1.10) HIGH");

    /* --- 2. Wire nrfx_pdm IRQ ---
     * Use IRQ_PRIO_LOWEST: Zephyr's nrfx glue ignores nrfx interrupt_priority
     * (NRFX_IRQ_PRIORITY_SET is a no-op); the only place priority is set is here. */
    IRQ_CONNECT(PDM_IRQn, IRQ_PRIO_LOWEST, nrfx_pdm_irq_handler, &pdm_inst, 0);
    irq_enable(PDM_IRQn);

    /* --- 3. Init nrfx_pdm --- */
    nrfx_pdm_config_t cfg = NRFX_PDM_DEFAULT_CONFIG(PDM_CLK_PIN, PDM_DIN_PIN);
    cfg.gain_l            = NRF_PDM_GAIN_MAXIMUM;
    cfg.gain_r            = NRF_PDM_GAIN_MAXIMUM;

    int err = nrfx_pdm_init(&pdm_inst, &cfg, pdm_event_handler);
    if (err < 0) {
        LOG_ERR("PDM: nrfx_pdm_init failed: %d", err);
        return;
    }

    /* --- 4. Precompute Hanning window and init FFT --- */
    for (int i = 0; i < PDM_BUF_SAMPLES; i++) {
        hann_window[i] = 0.5f * (1.0f - cosf(2.0f * (float)M_PI * i / (PDM_BUF_SAMPLES - 1)));
    }
    arm_rfft_fast_init_1024_f32(&fft_inst);

    /* --- 5. Init work item and semaphore --- */
    k_work_init(&pdm_process_work, pdm_process_work_handler);
    k_sem_init(&ack_sem, 0, 1);

    /* --- 6. Load persisted settings (threshold) --- */
    int settings_err = settings_load_subtree("pdm");
    if (settings_err) {
        LOG_WRN("PDM: settings load failed: %d (using default threshold)", settings_err);
    } else {
        LOG_INF("PDM: threshold loaded: %.2f", (double)detect_threshold);
    }

    LOG_INF("PDM: Initialized — capture starts on demand");
}

void pdm_manager_verbose_start(void) {
    pdm_verbose = true;
    if (!pdm_capture_active) {
        int err = nrfx_pdm_start(&pdm_inst);
        if (err < 0) {
            LOG_ERR("PDM: verbose start failed: %d", err);
        } else {
            pdm_verbose_own = true;
        }
    }
    /* if pdm_capture_active, PDM is already running — verbose piggybacks */
}

void pdm_manager_verbose_stop(void) {
    pdm_verbose = false;
    if (pdm_verbose_own) {
        nrfx_pdm_stop(&pdm_inst);
        pdm_verbose_own = false;
    }
}

void pdm_manager_set_threshold(float t) {
    detect_threshold = t;
}
void pdm_manager_save_threshold(float t) {
    detect_threshold = t;
    int err = settings_save_one("pdm/threshold", &t, sizeof(float));
    if (err) {
        LOG_ERR("PDM: threshold save failed: %d", err);
    }
}
float pdm_manager_get_threshold(void) {
    return detect_threshold;
}
```
